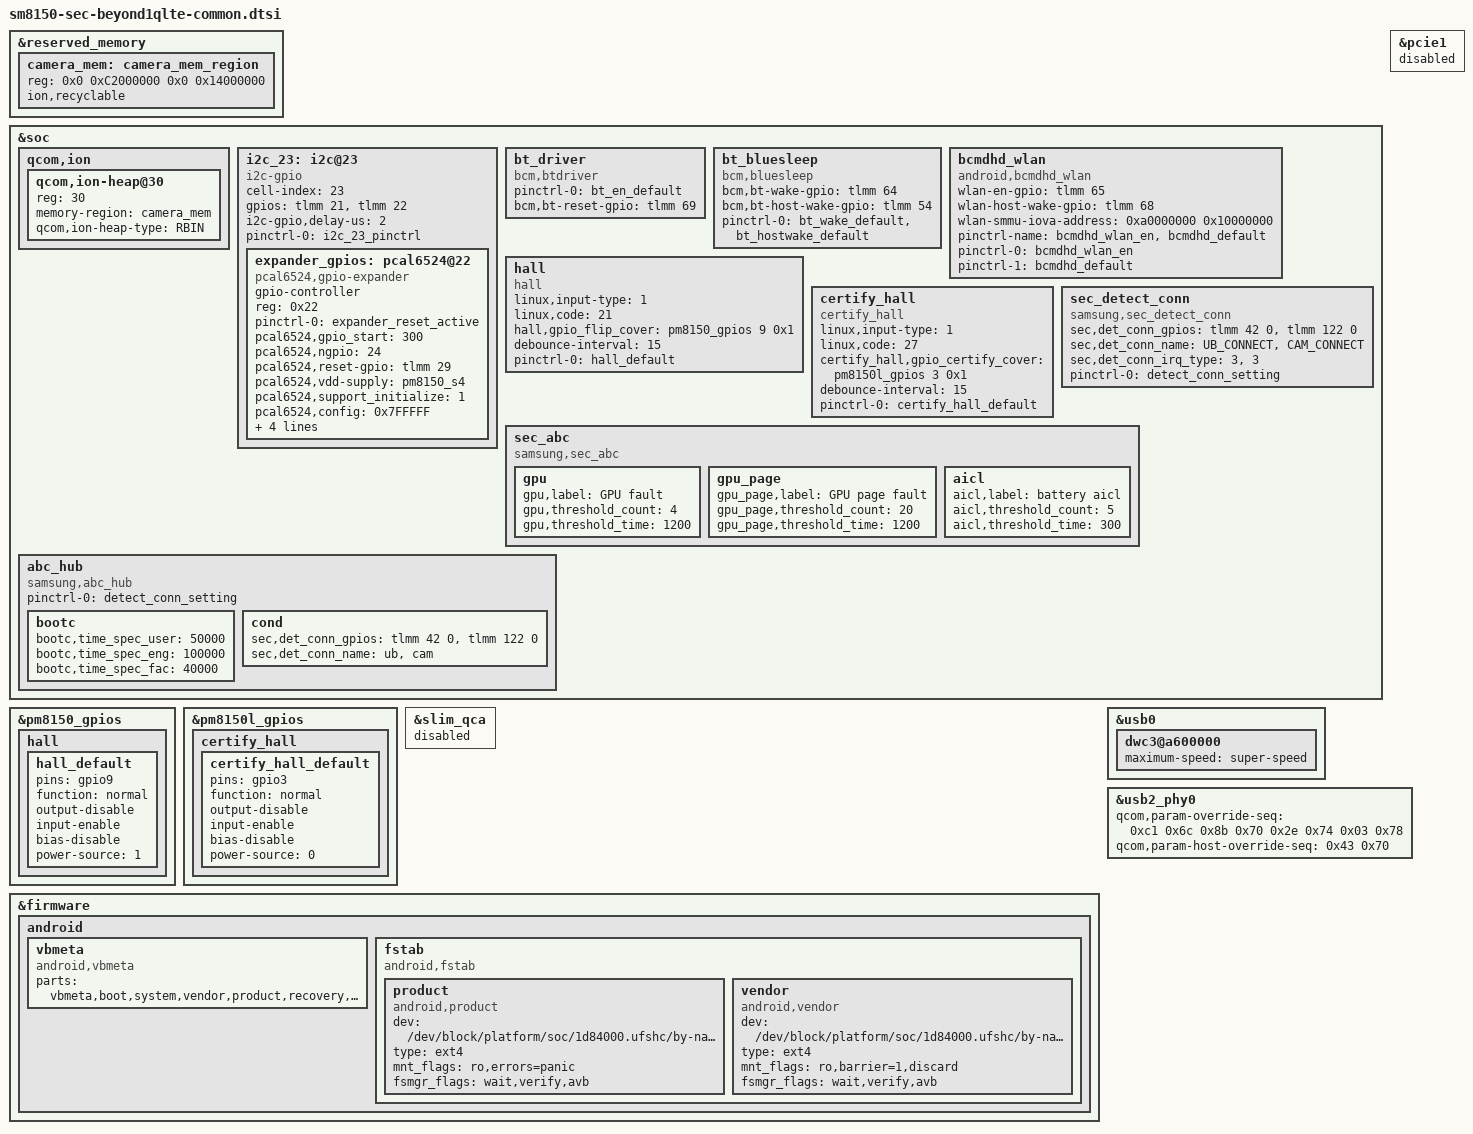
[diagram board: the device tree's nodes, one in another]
/* Copyright (c) 2016-2017, The Linux Foundation. All rights reserved.
 *
 * This program is free software; you can redistribute it and/or modify
 * it under the terms of the GNU General Public License version 2 and
 * only version 2 as published by the Free Software Foundation.
 *
 * This program is distributed in the hope that it will be useful,
 * but WITHOUT ANY WARRANTY; without even the implied warranty of
 * MERCHANTABILITY or FITNESS FOR A PARTICULAR PURPOSE.  See the
 * GNU General Public License for more details.
 */

#include "sm8150-sec-beyondq-audio.dtsi"

&reserved_memory {
	camera_mem: camera_mem_region {
		reg = <0x0 0xC2000000 0x0 0x14000000>;
		ion,recyclable;
	};
};

&soc {
	qcom,ion {
		qcom,ion-heap@30 { /* CAMERA HEAP  */
			reg = <30>;
			memory-region = <&camera_mem>;
			qcom,ion-heap-type = "RBIN";
		};
	};
};

&pm8150_gpios {
	hall {
		hall_default: hall_default {
			pins = "gpio9";
			function = "normal";
			output-disable;
			input-enable;
			bias-disable;
			power-source = <1>;
		};
	};
};

&pm8150l_gpios {
	certify_hall {
		certify_hall_default: certify_hall_default {
			pins = "gpio3";
			function = "normal";
			output-disable;
			input-enable;
			bias-disable;
			power-source = <0>;
		};
	};
};

&soc {
	i2c_23: i2c@23 {
		status = "ok";

		cell-index = <23>;
		compatible = "i2c-gpio";
		gpios = <&tlmm 21 0	/* EXPANDER_I2C_SDA_1P8 */
			 &tlmm 22 0	/* EXPANDER_I2C_SCL_1P8 */
		>;
		i2c-gpio,delay-us = <2>;
		#address-cells = <1>;
		#size-cells = <0>;

		pinctrl-names = "default";
		pinctrl-0 = <&i2c_23_pinctrl>;

		expander_gpios: pcal6524@22 {
			compatible = "pcal6524,gpio-expander";
			gpio-controller;
			#gpio-cells = <2>;
			reg = <0x22>;
			pinctrl-names = "expander_reset_setting";
			pinctrl-0 = <&expander_reset_active>;
			pcal6524,gpio_start = <300>;
			pcal6524,ngpio = <24>;
			pcal6524,reset-gpio = <&tlmm 29 0>;
			pcal6524,vdd-supply = <&pm8150_s4>;
			pcal6524,support_initialize = <1>;
			/* config, 24 ~ 0, 1bit configure[1:input, 0:output]*/
			pcal6524,config = <0x7FFFFF>;    /* P2[01111111] P1[11111111] P0[11111111] */
			/* data_out, 24 ~ 0, 1bit configure[1:high, 0:low]*/
			pcal6524,data_out = <0x000000>;  /* P2[00000000] P1[00000000] P0[00000000] */
			/* pull_reg, 8 ~ 0, 2bit configure[00:no_pull, 01:pull_down, 10:pull_up, 11:not used] */
			pcal6524,pull_reg_p0 = <0x0000>; /* 00 00 00 00 / 00 00 00 00 */
			pcal6524,pull_reg_p1 = <0x0000>; /* 00 00 00 00 / 00 00 00 00 */
			pcal6524,pull_reg_p2 = <0x0000>; /* 00 00 00 00 / 00 00 00 00 */
		};
	};
	
	bt_driver {
		compatible = "bcm,btdriver";  //bt_en
		pinctrl-names = "default";
		pinctrl-0 = <&bt_en_default>;
		bcm,bt-reset-gpio = <&tlmm 69 GPIO_ACTIVE_HIGH>;
		status = "okay";
	};

	bt_bluesleep {
		compatible = "bcm,bluesleep";
		bcm,bt-wake-gpio = <&tlmm 64 0>;
		bcm,bt-host-wake-gpio = <&tlmm 54 0>;
		pinctrl-names = "default";
		pinctrl-0 = <&bt_wake_default &bt_hostwake_default>;
		status = "okay";
	};

       bcmdhd_wlan {
		 compatible = "android,bcmdhd_wlan";
		 wlan-en-gpio = <&tlmm 65 0>;
		 wlan-host-wake-gpio = <&tlmm 68 0>;
		 wlan-smmu-iova-address = <0xa0000000 0x10000000>;
		 pinctrl-name = "bcmdhd_wlan_en","bcmdhd_default";
		 pinctrl-0 = <&bcmdhd_wlan_en>;
		 pinctrl-1 = <&bcmdhd_default>;
		 status = "ok";
	};

        hall {
                status = "okay";
                compatible = "hall";
                linux,input-type = <1>;
                linux,code = <21>;
                hall,gpio_flip_cover = <&pm8150_gpios 9 0x1>;
                debounce-interval = <15>;
		pinctrl-names = "default";
	        pinctrl-0 = <&hall_default>;
        };

        certify_hall {
                compatible = "certify_hall";
                linux,input-type = <1>;
                linux,code = <27>;
                certify_hall,gpio_certify_cover = <&pm8150l_gpios 3 0x1>;
                debounce-interval = <15>;
		pinctrl-names = "default";
	        pinctrl-0 = <&certify_hall_default>;
        };

	sec_detect_conn {
		compatible = "samsung,sec_detect_conn";
		sec,det_conn_gpios = <&tlmm 42 0 /* UB_CON_DETECT */
					&tlmm 122 0>; /* CAM_DETECT */

		sec,det_conn_name = "UB_CONNECT", "CAM_CONNECT";

		sec,det_conn_irq_type = <3>, /* UB_CON_DETECT FALLING, RIGING EDGE*/
					<3>; /* CAM_DETECT FALLING, RIGING EDGE*/

		pinctrl-names = "det_ap_connect";
		pinctrl-0 = <&detect_conn_setting>;
	};

	sec_abc {
		compatible = "samsung,sec_abc";
		status = "okay";

		gpu {
			gpu,label="GPU fault";
			gpu,threshold_count=<4>;
			gpu,threshold_time=<1200>;
		};
		gpu_page {
			gpu_page,label="GPU page fault";
			gpu_page,threshold_count=<20>;
			gpu_page,threshold_time=<1200>;
		};
		aicl {
			aicl,label="battery aicl";
			aicl,threshold_count=<5>;
			aicl,threshold_time=<300>;
		};
	};

	abc_hub {
		compatible = "samsung,abc_hub";
		status = "okay";

		pinctrl-names = "det_ap_connect";
		pinctrl-0 = <&detect_conn_setting>;

		bootc {
			bootc,time_spec_user = <50000>; /* user binary user build */
			bootc,time_spec_eng = <100000>; /* user binary eng build */
			bootc,time_spec_fac = <40000>; /* factory binary */
		};

		cond {
			sec,det_conn_gpios = <&tlmm 42 0 /* UB_CON_DETECT */
						&tlmm 122 0>; /* CAM_DETECT */
			sec,det_conn_name = "ub", "cam";
		};
	};
};

&slim_qca {
	status = "disabled";
};

&firmware {
	android {
		vbmeta {
			compatible = "android,vbmeta";
			parts = "vbmeta,boot,system,vendor,product,recovery,dtbo,abl,xbl,tz,hyp";
		};
		fstab {
			compatible = "android,fstab";
			product {
				compatible = "android,product";
				/* dev = "/dev/block/bootdevice/by-name/product"; */
				dev = "/dev/block/platform/soc/1d84000.ufshc/by-name/product";
				type = "ext4";
				mnt_flags = "ro,errors=panic";
				fsmgr_flags = "wait,verify,avb";
			};
			vendor {
				compatible = "android,vendor";
				/*dev = "/dev/block/bootdevice/by-name/vendor";*/
				dev = "/dev/block/platform/soc/1d84000.ufshc/by-name/vendor";
				type = "ext4";
				mnt_flags = "ro,barrier=1,discard";
				fsmgr_flags = "wait,verify,avb";
			};
		};
	};
};

&pcie1 {
	status = "disabled";
};

&usb0 {
	dwc3@a600000 {
		maximum-speed = "super-speed";
	};
};

&usb2_phy0 {
	qcom,param-override-seq =
		<0xc1 0x6c
		 0x8b 0x70
		 0x2e 0x74
		 0x03 0x78>;
	qcom,param-host-override-seq =
		<0x43 0x70>;
};
